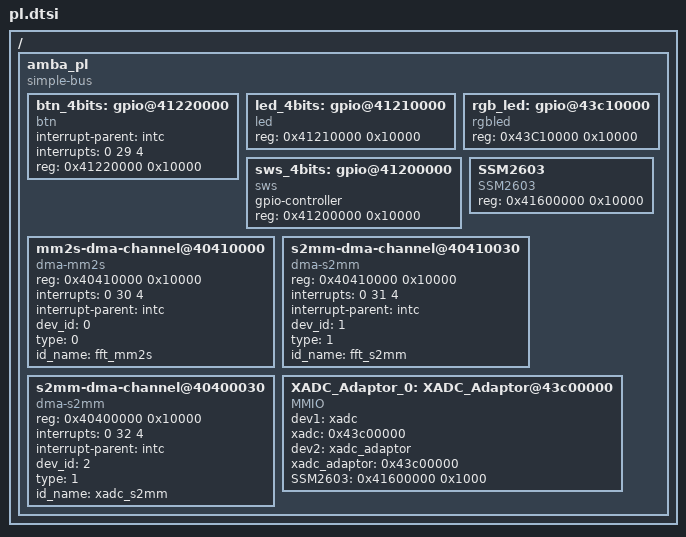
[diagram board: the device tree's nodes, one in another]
/*
 * CAUTION: This file is automatically generated by Xilinx.
 * Version:  
 * Today is: Wed Dec 19 13:38:34 2018
 */


/ {
	amba_pl: amba_pl {
		#address-cells = <1>;
		#size-cells = <1>;
		compatible = "simple-bus";
		ranges ;
		btn_4bits: gpio@41220000 {
			compatible = "btn";
			interrupt-parent = <&intc>;
			interrupts = <0 29 4>;
			reg = <0x41220000 0x10000>;
		};
		led_4bits: gpio@41210000 {
			compatible = "led";
			reg = <0x41210000 0x10000>;
		};
		rgb_led: gpio@43c10000 {
			compatible = "rgbled";
			reg = <0x43C10000 0x10000>;
		};
		sws_4bits: gpio@41200000 {
			compatible = "sws";
			gpio-controller ;
			reg = <0x41200000 0x10000>;
		};
		SSM2603 {
			compatible = "SSM2603";
			reg = <0x41600000 0x10000>;
		};
		
		mm2s-dma-channel@40410000 {
			compatible = "dma-mm2s";
			reg = <0x40410000 0x10000>;
			interrupts = <0 30 4>;
			interrupt-parent = <&intc>;
			dev_id = <0>;
			type = <0>;
			id_name = "fft_mm2s";
		};
		s2mm-dma-channel@40410030 {
			compatible = "dma-s2mm";
			reg = <0x40410000 0x10000>;
			interrupts = <0 31 4>;
			interrupt-parent = <&intc>;
			dev_id = <1>;
			type = <1>;
			id_name = "fft_s2mm";
		};
		s2mm-dma-channel@40400030 {
			compatible = "dma-s2mm";
			reg = <0x40400000 0x10000>;
			interrupts = <0 32 4>;
			interrupt-parent = <&intc>;
			dev_id = <2>;
			type = <1>;
			id_name = "xadc_s2mm";
		};
		
	
		XADC_Adaptor_0: XADC_Adaptor@43c00000 {
			compatible = "MMIO";
			dev1 = "xadc";
			xadc = <0x43c00000>;
			dev2 = "xadc_adaptor";
			xadc_adaptor = <0x43c00000>;
			SSM2603 = <0x41600000 0x1000>;
		};
	};
};
